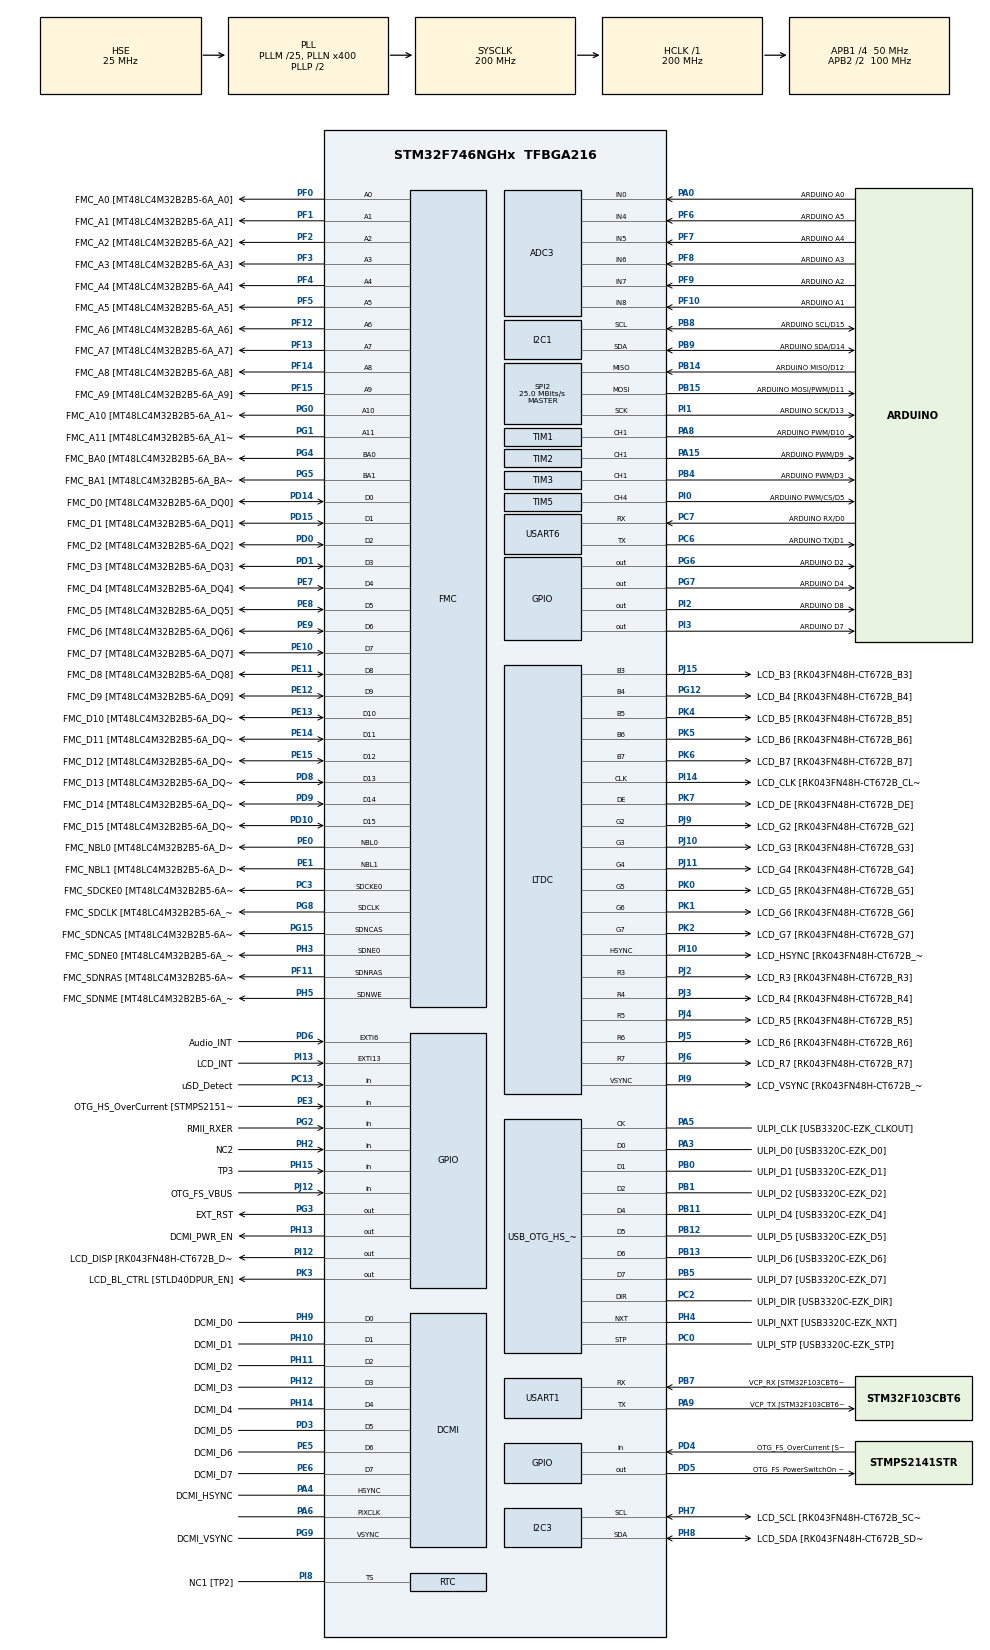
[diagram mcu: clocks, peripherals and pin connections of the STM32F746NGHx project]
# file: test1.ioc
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ADC3.Channel=ADC_CHANNEL_7
ADC3.Channel-0\#ChannelRegularConversion=ADC_CHANNEL_4
ADC3.Channel-IN0=ADC_CHANNEL_0
ADC3.Channel-IN4=ADC_CHANNEL_4
ADC3.Channel-IN5=ADC_CHANNEL_5
ADC3.Channel-IN6=ADC_CHANNEL_6
ADC3.Channel-IN7=ADC_CHANNEL_7
ADC3.Channel-IN8=ADC_CHANNEL_8
CORTEX_M7.CPU_DCache=Enabled
CORTEX_M7.CPU_ICache=Enabled
DCMI.ByteSelectMode=DCMI_BSM_ALTERNATE_2
DCMI.LineSelectMode=DCMI_LSM_ALTERNATE_2
DCMI.VSPolarity=DCMI_VSPOLARITY_HIGH
Dma.DCMI.0.Direction=DMA_PERIPH_TO_MEMORY
Dma.DCMI.0.FIFOMode=DMA_FIFOMODE_ENABLE
Dma.DCMI.0.FIFOThreshold=DMA_FIFO_THRESHOLD_FULL
Dma.DCMI.0.Instance=DMA2_Stream1
Dma.DCMI.0.MemBurst=DMA_MBURST_INC4
Dma.DCMI.0.MemDataAlignment=DMA_MDATAALIGN_WORD
Dma.DCMI.0.MemInc=DMA_MINC_ENABLE
Dma.DCMI.0.Mode=DMA_CIRCULAR
Dma.DCMI.0.PeriphBurst=DMA_PBURST_SINGLE
Dma.DCMI.0.PeriphDataAlignment=DMA_PDATAALIGN_WORD
Dma.DCMI.0.PeriphInc=DMA_PINC_DISABLE
Dma.DCMI.0.Priority=DMA_PRIORITY_HIGH
Dma.Request0=DCMI
FMC.CASLatency1=FMC_SDRAM_CAS_LATENCY_3
FMC.ColumnBitsNumber1=FMC_SDRAM_COLUMN_BITS_NUM_8
FMC.ExitSelfRefreshDelay1=7
FMC.LoadToActiveDelay1=2
FMC.RCDDelay1=2
FMC.RPDelay1=2
FMC.RPDelay2=2
FMC.RowCycleDelay1=7
FMC.RowCycleDelay2=7
FMC.SDClockPeriod1=FMC_SDRAM_CLOCK_PERIOD_2
FMC.SDClockPeriod2=FMC_SDRAM_CLOCK_PERIOD_2
FMC.SelfRefreshTime1=4
FMC.WriteRecoveryTime1=3
I2C1.Timing=0x00C0EAFF
I2C3.Timing=0x00C0EAFF
LTDC.ActiveH=240
LTDC.ActiveW=320
LTDC.HSync=1
LTDC.Layers=0
LTDC.PixelFormat_L0=LTDC_PIXEL_FORMAT_RGB565
LTDC.VSPolarity=LTDC_VSPOLARITY_AH
LTDC.VSync=1
LTDC.WindowX0_L1=0
LTDC.WindowX1_L0=320
LTDC.WindowX1_L1=320
LTDC.WindowY0_L1=0
LTDC.WindowY1_L0=240
LTDC.WindowY1_L1=240
Mcu.Family=STM32F7
Mcu.Name=STM32F746NGHx
Mcu.Package=TFBGA216
NVIC.DCMI_IRQn=true\:0\:0\:false\:false\:true\:true\:true\:true
NVIC.DMA2_Stream1_IRQn=true\:0\:0\:false\:false\:true\:false\:true\:true
NVIC.LTDC_ER_IRQn=true\:0\:0\:false\:false\:true\:true\:true\:true
NVIC.LTDC_IRQn=true\:0\:0\:false\:false\:true\:true\:true\:true
NVIC.PriorityGroup=NVIC_PRIORITYGROUP_4
NVIC.TIM6_DAC_IRQn=true\:15\:0\:false\:false\:true\:false\:true\:true
NVIC.TimeBase=TIM6_DAC_IRQn
NVIC.TimeBaseIP=TIM6
PA0/WKUP.GPIO_Label=ARDUINO A0
PA0/WKUP.GPIO_Mode=GPIO_MODE_ANALOG
PA0/WKUP.GPIO_PuPd=GPIO_NOPULL
PA0/WKUP.Signal=ADCx_IN0
PA1.GPIO_Label=RMII_REF_CLK [LAN8742A-CZ-TR_REFCLK0]
PA1.Signal=ETH_REF_CLK
PA10.GPIO_Label=OTG_FS_ID
PA10.Signal=USB_OTG_FS_ID
PA11.GPIO_Label=OTG_FS_N
PA11.Signal=USB_OTG_FS_DM
PA12.GPIO_Label=OTG_FS_P
PA12.Signal=USB_OTG_FS_DP
PA13.GPIO_Label=SWDIO
PA13.Mode=Serial_Wire
PA13.Signal=SYS_JTMS-SWDIO
PA14.GPIO_Label=SWCLK
PA14.Mode=Serial_Wire
PA14.Signal=SYS_JTCK-SWCLK
PA15.GPIO_Label=ARDUINO PWM/D9
PA15.GPIO_ModeDefaultPP=GPIO_MODE_AF_PP
PA15.GPIO_PuPd=GPIO_NOPULL
PA15.GPIO_Speed=GPIO_SPEED_FREQ_LOW
PA15.Signal=S_TIM2_CH1_ETR
PA2.GPIO_Label=RMII_MDIO [LAN8742A-CZ-TR_MDIO]
PA2.Signal=ETH_MDIO
PA3.GPIO_Label=ULPI_D0 [USB3320C-EZK_D0]
PA3.Mode=Host_HS
PA3.Signal=USB_OTG_HS_ULPI_D0
PA4.GPIO_Label=DCMI_HSYNC
PA4.Mode=Slave_8_bits_External_Synchro
PA4.Signal=DCMI_HSYNC
PA5.GPIO_Label=ULPI_CLK [USB3320C-EZK_CLKOUT]
PA5.Mode=Host_HS
PA5.Signal=USB_OTG_HS_ULPI_CK
PA6.Mode=Slave_8_bits_External_Synchro
PA6.Signal=DCMI_PIXCLK
PA7.GPIO_Label=RMII_CRS_DV [LAN8742A-CZ-TR_CRS_DV]
PA7.Signal=ETH_CRS_DV
PA8.GPIO_Label=ARDUINO PWM/D10
PA8.GPIO_ModeDefaultPP=GPIO_MODE_AF_PP
PA8.GPIO_PuPd=GPIO_NOPULL
PA8.GPIO_Speed=GPIO_SPEED_FREQ_LOW
PA8.Signal=S_TIM1_CH1
PA9.GPIO_Label=VCP_TX [STM32F103CBT6_PA3]
PA9.GPIO_Mode=GPIO_MODE_AF_PP
PA9.GPIO_PuPd=GPIO_NOPULL
PA9.GPIO_Speed=GPIO_SPEED_FREQ_LOW
PA9.Mode=Asynchronous
PA9.Signal=USART1_TX
PB0.GPIO_Label=ULPI_D1 [USB3320C-EZK_D1]
PB0.Mode=Host_HS
PB0.Signal=USB_OTG_HS_ULPI_D1
PB1.GPIO_Label=ULPI_D2 [USB3320C-EZK_D2]
PB1.Mode=Host_HS
PB1.Signal=USB_OTG_HS_ULPI_D2
PB10.GPIO_Label=ULPI_D3 [USB3320C-EZK_D3]
PB10.Signal=USB_OTG_HS_ULPI_D3
PB11.GPIO_Label=ULPI_D4 [USB3320C-EZK_D4]
PB11.Mode=Host_HS
PB11.Signal=USB_OTG_HS_ULPI_D4
PB12.GPIO_Label=ULPI_D5 [USB3320C-EZK_D5]
PB12.Mode=Host_HS
PB12.Signal=USB_OTG_HS_ULPI_D5
PB13.GPIO_Label=ULPI_D6 [USB3320C-EZK_D6]
PB13.Mode=Host_HS
PB13.Signal=USB_OTG_HS_ULPI_D6
PB14.GPIO_Label=ARDUINO MISO/D12
PB14.GPIO_Mode=GPIO_MODE_AF_PP
PB14.GPIO_PuPd=GPIO_NOPULL
PB14.GPIO_Speed=GPIO_SPEED_FREQ_LOW
PB14.Mode=Full_Duplex_Master
PB14.Signal=SPI2_MISO
PB15.GPIO_Label=ARDUINO MOSI/PWM/D11
PB15.GPIO_Mode=GPIO_MODE_AF_PP
PB15.GPIO_PuPd=GPIO_NOPULL
PB15.GPIO_Speed=GPIO_SPEED_FREQ_LOW
PB15.Mode=Full_Duplex_Master
PB15.Signal=SPI2_MOSI
PB2.Signal=QUADSPI_CLK
PB3.GPIO_Label=SWO
PB3.Signal=SYS_JTDO-SWO
PB4.GPIO_Label=ARDUINO PWM/D3
PB4.GPIO_ModeDefaultPP=GPIO_MODE_AF_PP
PB4.GPIO_PuPd=GPIO_NOPULL
PB4.GPIO_Speed=GPIO_SPEED_FREQ_LOW
PB4.Signal=S_TIM3_CH1
PB5.GPIO_Label=ULPI_D7 [USB3320C-EZK_D7]
PB5.Mode=Host_HS
PB5.Signal=USB_OTG_HS_ULPI_D7
PB6.GPIO_Label=QSPI_NCS [N25Q128A13EF840E_S]
PB6.Signal=QUADSPI_BK1_NCS
PB7.GPIO_Label=VCP_RX [STM32F103CBT6_PA2]
PB7.GPIO_Mode=GPIO_MODE_AF_PP
PB7.GPIO_PuPd=GPIO_NOPULL
PB7.GPIO_Speed=GPIO_SPEED_FREQ_LOW
PB7.Mode=Asynchronous
PB7.Signal=USART1_RX
PB8.GPIO_Label=ARDUINO SCL/D15
PB8.GPIO_Mode=GPIO_MODE_AF_OD
PB8.GPIO_Pu=GPIO_PULLUP
PB8.GPIO_PuPd=GPIO_NOPULL
PB8.GPIO_Speed=GPIO_SPEED_FREQ_LOW
PB8.Mode=I2C
PB8.Signal=I2C1_SCL
PB9.GPIO_Label=ARDUINO SDA/D14
PB9.GPIO_Mode=GPIO_MODE_AF_OD
PB9.GPIO_Pu=GPIO_PULLUP
PB9.GPIO_PuPd=GPIO_NOPULL
PB9.GPIO_Speed=GPIO_SPEED_FREQ_LOW
PB9.Mode=I2C
PB9.Signal=I2C1_SDA
PC0.GPIO_Label=ULPI_STP [USB3320C-EZK_STP]
PC0.Mode=Host_HS
PC0.Signal=USB_OTG_HS_ULPI_STP
PC1.GPIO_Label=RMII_MDC [LAN8742A-CZ-TR_MDC]
PC1.Signal=ETH_MDC
PC10.GPIO_Label=SDMMC_D2
PC10.Signal=SDMMC1_D2
PC11.GPIO_Label=SDMMC_D3
PC11.Signal=SDMMC1_D3
PC12.GPIO_Label=SDMMC_CK
PC12.Signal=SDMMC1_CK
PC13.GPIO_Label=uSD_Detect
PC13.Signal=GPIO_Input
PC14/OSC32_IN.GPIO_Label=RCC_OSC32_IN
PC14/OSC32_IN.Mode=LSE-External-Oscillator
PC14/OSC32_IN.Signal=RCC_OSC32_IN
PC15/OSC32_OUT.GPIO_Label=RCC_OSC32_OUT
PC15/OSC32_OUT.Mode=LSE-External-Oscillator
PC15/OSC32_OUT.Signal=RCC_OSC32_OUT
PC2.GPIO_Label=ULPI_DIR [USB3320C-EZK_DIR]
PC2.Mode=Host_HS
PC2.Signal=USB_OTG_HS_ULPI_DIR
PC3.GPIO_Label=FMC_SDCKE0 [MT48LC4M32B2B5-6A_CKE]
PC3.Mode=SdramChipSelect1_1
PC3.Signal=FMC_SDCKE0
PC4.GPIO_Label=RMII_RXD0 [LAN8742A-CZ-TR_RXD0]
PC4.Signal=ETH_RXD0
PC5.GPIO_Label=RMII_RXD1 [LAN8742A-CZ-TR_RXD1]
PC5.Signal=ETH_RXD1
PC6.GPIO_Label=ARDUINO TX/D1
PC6.Mode=Asynchronous
PC6.Signal=USART6_TX
PC7.GPIO_Label=ARDUINO RX/D0
PC7.Mode=Asynchronous
PC7.Signal=USART6_RX
PC8.Signal=SDMMC1_D0
PC9.Signal=SDMMC1_D1
PD0.GPIO_Label=FMC_D2 [MT48LC4M32B2B5-6A_DQ2]
PD0.Signal=FMC_D2_DA2
PD1.GPIO_Label=FMC_D3 [MT48LC4M32B2B5-6A_DQ3]
PD1.Signal=FMC_D3_DA3
PD10.GPIO_Label=FMC_D15 [MT48LC4M32B2B5-6A_DQ15]
PD10.Signal=FMC_D15_DA15
PD11.GPIO_Label=QSPI_D0 [N25Q128A13EF840E_DQ0]
PD11.Signal=QUADSPI_BK1_IO0
PD12.GPIO_Label=QSPI_D1 [N25Q128A13EF840E_DQ1]
PD12.Signal=QUADSPI_BK1_IO1
PD13.GPIO_Label=QSPI_D3 [N25Q128A13EF840E_DQ3]
PD13.Signal=QUADSPI_BK1_IO3
PD14.GPIO_Label=FMC_D0 [MT48LC4M32B2B5-6A_DQ0]
PD14.Signal=FMC_D0_DA0
PD15.GPIO_Label=FMC_D1 [MT48LC4M32B2B5-6A_DQ1]
PD15.Signal=FMC_D1_DA1
PD2.GPIO_Label=SDMMC_CMD
PD2.Signal=SDMMC1_CMD
PD3.GPIO_Label=DCMI_D5
PD3.Mode=Slave_8_bits_External_Synchro
PD3.Signal=DCMI_D5
PD4.GPIO_Label=OTG_FS_OverCurrent [STMPS2141STR_Fault]
PD4.Signal=GPIO_Input
PD5.GPIO_Label=OTG_FS_PowerSwitchOn [STMPS2141STR_EN]
PD5.PinState=GPIO_PIN_SET
PD5.Signal=GPIO_Output
PD6.GPIO_Label=Audio_INT
PD6.GPIO_ModeDefaultEXTI=GPIO_MODE_EVT_RISING
PD6.Signal=GPXTI6
PD7.GPIO_Label=SPDIF_RX0 [74LVC1G04SE_4]
PD7.Signal=SPDIFRX_IN0
PD8.GPIO_Label=FMC_D13 [MT48LC4M32B2B5-6A_DQ13]
PD8.Signal=FMC_D13_DA13
PD9.GPIO_Label=FMC_D14 [MT48LC4M32B2B5-6A_DQ14]
PD9.Signal=FMC_D14_DA14
PE0.GPIO_Label=FMC_NBL0 [MT48LC4M32B2B5-6A_DQM0]
PE0.Signal=FMC_NBL0
PE1.GPIO_Label=FMC_NBL1 [MT48LC4M32B2B5-6A_DQM1]
PE1.Signal=FMC_NBL1
PE10.GPIO_Label=FMC_D7 [MT48LC4M32B2B5-6A_DQ7]
PE10.Signal=FMC_D7_DA7
PE11.GPIO_Label=FMC_D8 [MT48LC4M32B2B5-6A_DQ8]
PE11.Signal=FMC_D8_DA8
PE12.GPIO_Label=FMC_D9 [MT48LC4M32B2B5-6A_DQ9]
PE12.Signal=FMC_D9_DA9
PE13.GPIO_Label=FMC_D10 [MT48LC4M32B2B5-6A_DQ10]
PE13.Signal=FMC_D10_DA10
PE14.GPIO_Label=FMC_D11 [MT48LC4M32B2B5-6A_DQ11]
PE14.Signal=FMC_D11_DA11
PE15.GPIO_Label=FMC_D12 [MT48LC4M32B2B5-6A_DQ12]
PE15.Signal=FMC_D12_DA12
PE2.GPIO_Label=QSPI_D2 [N25Q128A13EF840E_DQ2]
PE2.Signal=QUADSPI_BK1_IO2
PE3.GPIO_Label=OTG_HS_OverCurrent [STMPS2151STR_FAULT]
PE3.Signal=GPIO_Input
PE4.GPIO_Label=LCD_B0 [RK043FN48H-CT672B_B0]
PE4.Signal=LTDC_B0
PE5.GPIO_Label=DCMI_D6
PE5.Mode=Slave_8_bits_External_Synchro
PE5.Signal=DCMI_D6
PE6.GPIO_Label=DCMI_D7
PE6.Mode=Slave_8_bits_External_Synchro
PE6.Signal=DCMI_D7
PE7.GPIO_Label=FMC_D4 [MT48LC4M32B2B5-6A_DQ4]
PE7.Signal=FMC_D4_DA4
PE8.GPIO_Label=FMC_D5 [MT48LC4M32B2B5-6A_DQ5]
PE8.Signal=FMC_D5_DA5
PE9.GPIO_Label=FMC_D6 [MT48LC4M32B2B5-6A_DQ6]
PE9.Signal=FMC_D6_DA6
PF0.GPIO_Label=FMC_A0 [MT48LC4M32B2B5-6A_A0]
PF0.Signal=FMC_A0
PF1.GPIO_Label=FMC_A1 [MT48LC4M32B2B5-6A_A1]
PF1.Signal=FMC_A1
PF10.GPIO_Label=ARDUINO A1
PF10.GPIO_Mode=GPIO_MODE_ANALOG
PF10.GPIO_PuPd=GPIO_NOPULL
PF10.Mode=IN8
PF10.Signal=ADC3_IN8
PF11.GPIO_Label=FMC_SDNRAS [MT48LC4M32B2B5-6A_RAS]
PF11.Signal=FMC_SDNRAS
PF12.GPIO_Label=FMC_A6 [MT48LC4M32B2B5-6A_A6]
PF12.Signal=FMC_A6
PF13.GPIO_Label=FMC_A7 [MT48LC4M32B2B5-6A_A7]
PF13.Signal=FMC_A7
PF14.GPIO_Label=FMC_A8 [MT48LC4M32B2B5-6A_A8]
PF14.Signal=FMC_A8
PF15.GPIO_Label=FMC_A9 [MT48LC4M32B2B5-6A_A9]
PF15.Signal=FMC_A9
PF2.GPIO_Label=FMC_A2 [MT48LC4M32B2B5-6A_A2]
PF2.Signal=FMC_A2
PF3.GPIO_Label=FMC_A3 [MT48LC4M32B2B5-6A_A3]
PF3.Signal=FMC_A3
PF4.GPIO_Label=FMC_A4 [MT48LC4M32B2B5-6A_A4]
PF4.Signal=FMC_A4
PF5.GPIO_Label=FMC_A5 [MT48LC4M32B2B5-6A_A5]
PF5.Signal=FMC_A5
PF6.GPIO_Label=ARDUINO A5
PF6.GPIO_Mode=GPIO_MODE_ANALOG
PF6.GPIO_PuPd=GPIO_NOPULL
PF6.Mode=IN4
PF6.Signal=ADC3_IN4
PF7.GPIO_Label=ARDUINO A4
PF7.GPIO_Mode=GPIO_MODE_ANALOG
PF7.GPIO_PuPd=GPIO_NOPULL
PF7.Mode=IN5
PF7.Signal=ADC3_IN5
PF8.GPIO_Label=ARDUINO A3
PF8.GPIO_Mode=GPIO_MODE_ANALOG
PF8.GPIO_PuPd=GPIO_NOPULL
PF8.Mode=IN6
PF8.Signal=ADC3_IN6
PF9.GPIO_Label=ARDUINO A2
PF9.GPIO_Mode=GPIO_MODE_ANALOG
PF9.GPIO_PuPd=GPIO_NOPULL
PF9.Mode=IN7
PF9.Signal=ADC3_IN7
PG0.GPIO_Label=FMC_A10 [MT48LC4M32B2B5-6A_A10]
PG0.Signal=FMC_A10
PG1.GPIO_Label=FMC_A11 [MT48LC4M32B2B5-6A_A11]
PG1.Signal=FMC_A11
PG10.GPIO_Label=SAI2_SDB [WM8994ECS/R_ADCDAT1]
PG10.Signal=SAI2_SD_B
PG11.GPIO_Label=RMII_TX_EN [LAN8742A-CZ-TR_TXEN]
PG11.Signal=ETH_TX_EN
PG12.GPIO_Label=LCD_B4 [RK043FN48H-CT672B_B4]
PG12.Mode=RGB565
PG12.Signal=LTDC_B4
PG13.GPIO_Label=RMII_TXD0 [LAN8742A-CZ-TR_TXD0]
PG13.Signal=ETH_TXD0
PG14.GPIO_Label=RMII_TXD1 [LAN8742A-CZ-TR_TXD1]
PG14.Signal=ETH_TXD1
PG15.GPIO_Label=FMC_SDNCAS [MT48LC4M32B2B5-6A_CAS]
PG15.Signal=FMC_SDNCAS
PG2.GPIO_Label=RMII_RXER
PG2.Signal=GPIO_Input
PG3.GPIO_Label=EXT_RST
PG3.Signal=GPIO_Output
PG4.GPIO_Label=FMC_BA0 [MT48LC4M32B2B5-6A_BA0]
PG4.Signal=FMC_A14_BA0
PG5.GPIO_Label=FMC_BA1 [MT48LC4M32B2B5-6A_BA1]
PG5.Signal=FMC_A15_BA1
PG6.GPIO_Label=ARDUINO D2
PG6.Signal=GPIO_Output
PG7.GPIO_Label=ARDUINO D4
PG7.Signal=GPIO_Output
PG8.GPIO_Label=FMC_SDCLK [MT48LC4M32B2B5-6A_CLK]
PG8.Signal=FMC_SDCLK
PG9.GPIO_Label=DCMI_VSYNC
PG9.Mode=Slave_8_bits_External_Synchro
PG9.Signal=DCMI_VSYNC
PH0/OSC_IN.GPIO_Label=OSC_25M [NZ2520SB-25.00M_OUT]
PH0/OSC_IN.Mode=HSE-External-Oscillator
PH0/OSC_IN.Signal=RCC_OSC_IN
PH1/OSC_OUT.Mode=HSE-External-Oscillator
PH1/OSC_OUT.Signal=RCC_OSC_OUT
PH10.GPIO_Label=DCMI_D1
PH10.Mode=Slave_8_bits_External_Synchro
PH10.Signal=DCMI_D1
PH11.GPIO_Label=DCMI_D2
PH11.Mode=Slave_8_bits_External_Synchro
PH11.Signal=DCMI_D2
PH12.GPIO_Label=DCMI_D3
PH12.Mode=Slave_8_bits_External_Synchro
PH12.Signal=DCMI_D3
PH13.GPIO_Label=DCMI_PWR_EN
PH13.Signal=GPIO_Output
PH14.GPIO_Label=DCMI_D4
PH14.Mode=Slave_8_bits_External_Synchro
PH14.Signal=DCMI_D4
PH15.GPIO_Label=TP3
PH15.Signal=GPIO_Input
PH2.GPIO_Label=NC2
PH2.Signal=GPIO_Input
PH3.GPIO_Label=FMC_SDNE0 [MT48LC4M32B2B5-6A_CS]
PH3.Mode=SdramChipSelect1_1
PH3.Signal=FMC_SDNE0
PH4.GPIO_Label=ULPI_NXT [USB3320C-EZK_NXT]
PH4.Mode=Host_HS
PH4.Signal=USB_OTG_HS_ULPI_NXT
PH5.GPIO_Label=FMC_SDNME [MT48LC4M32B2B5-6A_WE]
PH5.Signal=FMC_SDNWE
PH6.GPIO_Label=ARDUINO PWM/D6
PH6.Signal=S_TIM12_CH1
PH7.GPIO_Label=LCD_SCL [RK043FN48H-CT672B_SCL]
PH7.GPIO_Pu=GPIO_PULLUP
PH7.Mode=I2C
PH7.Signal=I2C3_SCL
PH8.GPIO_Label=LCD_SDA [RK043FN48H-CT672B_SDA]
PH8.GPIO_Pu=GPIO_PULLUP
PH8.Mode=I2C
PH8.Signal=I2C3_SDA
PH9.GPIO_Label=DCMI_D0
PH9.Mode=Slave_8_bits_External_Synchro
PH9.Signal=DCMI_D0
PI0.GPIO_Label=ARDUINO PWM/CS/D5
PI0.GPIO_ModeDefaultPP=GPIO_MODE_AF_PP
PI0.GPIO_PuPd=GPIO_NOPULL
PI0.GPIO_Speed=GPIO_SPEED_FREQ_LOW
PI0.Signal=S_TIM5_CH4
PI1.GPIO_Label=ARDUINO SCK/D13
PI1.GPIO_Mode=GPIO_MODE_AF_PP
PI1.GPIO_PuPd=GPIO_NOPULL
PI1.GPIO_Speed=GPIO_SPEED_FREQ_LOW
PI1.Mode=Full_Duplex_Master
PI1.Signal=SPI2_SCK
PI10.GPIO_Label=LCD_HSYNC [RK043FN48H-CT672B_HSYNC]
PI10.Mode=RGB565
PI10.Signal=LTDC_HSYNC
PI12.GPIO_Label=LCD_DISP [RK043FN48H-CT672B_DISP] 
PI12.PinState=GPIO_PIN_SET
PI12.Signal=GPIO_Output
PI13.GPIO_Label=LCD_INT
PI13.GPIO_ModeDefaultEXTI=GPIO_MODE_EVT_RISING
PI13.Signal=GPXTI13
PI14.GPIO_Label=LCD_CLK [RK043FN48H-CT672B_CLK]
PI14.Mode=RGB565
PI14.Signal=LTDC_CLK
PI15.GPIO_Label=LCD_R0 [RK043FN48H-CT672B_R0]
PI15.Signal=LTDC_R0
PI2.GPIO_Label=ARDUINO D8
PI2.Signal=GPIO_Output
PI3.GPIO_Label=ARDUINO D7
PI3.Signal=GPIO_Output
PI4.GPIO_Label=SAI2_MCLKA [WM8994ECS/R_MCLK1]
PI4.Signal=SAI2_MCLK_A
PI5.GPIO_Label=SAI2_SCKA [WM8994ECS/R_BCLK1]
PI5.Signal=SAI2_SCK_A
PI6.GPIO_Label=SAI2_SDA [WM8994ECS/R_DACDAT1]
PI6.Signal=SAI2_SD_A
PI7.GPIO_Label=SAI2_FSA [WM8994ECS/R_LRCLK1]
PI7.Signal=SAI2_FS_A
PI8.GPIO_Label=NC1 [TP2]
PI8.Mode=Timestamp enabled - Input Enabled to TS
PI8.Signal=RTC_TS
PI9.GPIO_Label=LCD_VSYNC [RK043FN48H-CT672B_VSYNC]
PI9.Mode=RGB565
PI9.Signal=LTDC_VSYNC
PJ0.GPIO_Label=LCD_R1 [RK043FN48H-CT672B_R1]
PJ0.Signal=LTDC_R1
PJ1.GPIO_Label=LCD_R2 [RK043FN48H-CT672B_R2]
PJ1.Signal=LTDC_R2
PJ10.GPIO_Label=LCD_G3 [RK043FN48H-CT672B_G3]
PJ10.Mode=RGB565
PJ10.Signal=LTDC_G3
PJ11.GPIO_Label=LCD_G4 [RK043FN48H-CT672B_G4]
PJ11.Mode=RGB565
PJ11.Signal=LTDC_G4
PJ12.GPIO_Label=OTG_FS_VBUS
PJ12.Signal=GPIO_Input
PJ13.GPIO_Label=LCD_B1 [RK043FN48H-CT672B_B1]
PJ13.Signal=LTDC_B1
PJ14.GPIO_Label=LCD_B2 [RK043FN48H-CT672B_B2]
PJ14.Signal=LTDC_B2
PJ15.GPIO_Label=LCD_B3 [RK043FN48H-CT672B_B3]
PJ15.Mode=RGB565
PJ15.Signal=LTDC_B3
PJ2.GPIO_Label=LCD_R3 [RK043FN48H-CT672B_R3]
PJ2.Mode=RGB565
PJ2.Signal=LTDC_R3
PJ3.GPIO_Label=LCD_R4 [RK043FN48H-CT672B_R4]
PJ3.Mode=RGB565
PJ3.Signal=LTDC_R4
PJ4.GPIO_Label=LCD_R5 [RK043FN48H-CT672B_R5]
PJ4.Mode=RGB565
PJ4.Signal=LTDC_R5
PJ5.GPIO_Label=LCD_R6 [RK043FN48H-CT672B_R6]
PJ5.Mode=RGB565
PJ5.Signal=LTDC_R6
PJ6.GPIO_Label=LCD_R7 [RK043FN48H-CT672B_R7]
PJ6.Mode=RGB565
PJ6.Signal=LTDC_R7
PJ7.GPIO_Label=LCD_G0 [RK043FN48H-CT672B_G0]
PJ7.Signal=LTDC_G0
PJ8.GPIO_Label=LCD_G1 [RK043FN48H-CT672B_G1]
PJ8.Signal=LTDC_G1
PJ9.GPIO_Label=LCD_G2 [RK043FN48H-CT672B_G2]
PJ9.Mode=RGB565
PJ9.Signal=LTDC_G2
PK0.GPIO_Label=LCD_G5 [RK043FN48H-CT672B_G5]
PK0.Mode=RGB565
PK0.Signal=LTDC_G5
PK1.GPIO_Label=LCD_G6 [RK043FN48H-CT672B_G6]
PK1.Mode=RGB565
PK1.Signal=LTDC_G6
PK2.GPIO_Label=LCD_G7 [RK043FN48H-CT672B_G7]
PK2.Mode=RGB565
PK2.Signal=LTDC_G7
PK3.GPIO_Label=LCD_BL_CTRL [STLD40DPUR_EN]
PK3.GPIO_Speed=GPIO_SPEED_FREQ_LOW
PK3.PinState=GPIO_PIN_SET
PK3.Signal=GPIO_Output
PK4.GPIO_Label=LCD_B5 [RK043FN48H-CT672B_B5]
PK4.Mode=RGB565
PK4.Signal=LTDC_B5
PK5.GPIO_Label=LCD_B6 [RK043FN48H-CT672B_B6]
PK5.Mode=RGB565
PK5.Signal=LTDC_B6
PK6.GPIO_Label=LCD_B7 [RK043FN48H-CT672B_B7]
PK6.Mode=RGB565
PK6.Signal=LTDC_B7
PK7.GPIO_Label=LCD_DE [RK043FN48H-CT672B_DE]
PK7.Mode=RGB565
PK7.Signal=LTDC_DE
ProjectManager.HeapSize=0x2000
ProjectManager.StackSize=0x2000
ProjectManager.TargetToolchain=MDK-ARM V5.32
RCC.AHBFreq_Value=200000000
RCC.APB1CLKDivider=RCC_HCLK_DIV4
RCC.APB1Freq_Value=50000000
RCC.APB1TimFreq_Value=100000000
RCC.APB2CLKDivider=RCC_HCLK_DIV2
RCC.APB2Freq_Value=100000000
RCC.APB2TimFreq_Value=200000000
RCC.CortexFreq_Value=200000000
RCC.HCLKFreq_Value=200000000
RCC.HSE_VALUE=25000000
RCC.HSI_VALUE=16000000
RCC.PLL48CLockSelection=RCC_CLK48SOURCE_PLLSAIP
RCC.PLLI2SN=100
RCC.PLLM=25
RCC.PLLN=400
RCC.PLLQ=9
RCC.PLLSAIN=288
RCC.PLLSAIP=RCC_PLLSAIP_DIV8
RCC.PLLSAIR=4
RCC.PLLSAIRDiv=RCC_PLLSAIDIVR_8
RCC.PLLSourceVirtual=RCC_PLLSOURCE_HSE
RCC.SDMMCClockSelection=RCC_SDMMC1CLKSOURCE_CLK48
RCC.SYSCLKFreq_VALUE=200000000
RCC.SYSCLKSource=RCC_SYSCLKSOURCE_PLLCLK
RCC.USBFreq_Value=36000000
RCC.VCOOutputFreq_Value=400000000
SH.ADCx_IN0.0=ADC3_IN0,IN0
SH.FMC_A0.0=FMC_A0,12b-sda1
SH.FMC_A1.0=FMC_A1,12b-sda1
SH.FMC_A10.0=FMC_A10,12b-sda1
SH.FMC_A11.0=FMC_A11,12b-sda1
SH.FMC_A14_BA0.0=FMC_BA0,FourSdramBanks1
SH.FMC_A15_BA1.0=FMC_BA1,FourSdramBanks1
SH.FMC_A2.0=FMC_A2,12b-sda1
SH.FMC_A3.0=FMC_A3,12b-sda1
SH.FMC_A4.0=FMC_A4,12b-sda1
SH.FMC_A5.0=FMC_A5,12b-sda1
SH.FMC_A6.0=FMC_A6,12b-sda1
SH.FMC_A7.0=FMC_A7,12b-sda1
SH.FMC_A8.0=FMC_A8,12b-sda1
SH.FMC_A9.0=FMC_A9,12b-sda1
SH.FMC_D0_DA0.0=FMC_D0,sd-16b-d1
SH.FMC_D10_DA10.0=FMC_D10,sd-16b-d1
SH.FMC_D11_DA11.0=FMC_D11,sd-16b-d1
SH.FMC_D12_DA12.0=FMC_D12,sd-16b-d1
SH.FMC_D13_DA13.0=FMC_D13,sd-16b-d1
SH.FMC_D14_DA14.0=FMC_D14,sd-16b-d1
SH.FMC_D15_DA15.0=FMC_D15,sd-16b-d1
SH.FMC_D1_DA1.0=FMC_D1,sd-16b-d1
SH.FMC_D2_DA2.0=FMC_D2,sd-16b-d1
SH.FMC_D3_DA3.0=FMC_D3,sd-16b-d1
SH.FMC_D4_DA4.0=FMC_D4,sd-16b-d1
SH.FMC_D5_DA5.0=FMC_D5,sd-16b-d1
SH.FMC_D6_DA6.0=FMC_D6,sd-16b-d1
SH.FMC_D7_DA7.0=FMC_D7,sd-16b-d1
SH.FMC_D8_DA8.0=FMC_D8,sd-16b-d1
SH.FMC_D9_DA9.0=FMC_D9,sd-16b-d1
SH.FMC_NBL0.0=FMC_NBL0,Sd2ByteEnable1
SH.FMC_NBL1.0=FMC_NBL1,Sd2ByteEnable1
SH.FMC_SDCLK.0=FMC_SDCLK,12b-sda1
SH.FMC_SDNCAS.0=FMC_SDNCAS,12b-sda1
SH.FMC_SDNRAS.0=FMC_SDNRAS,12b-sda1
SH.FMC_SDNWE.0=FMC_SDNWE,12b-sda1
SH.S_TIM12_CH1.0=TIM12_CH1
SH.S_TIM1_CH1.0=TIM1_CH1,PWM Generation1 CH1
SH.S_TIM2_CH1_ETR.0=TIM2_CH1,PWM Generation1 CH1
SH.S_TIM3_CH1.0=TIM3_CH1,PWM Generation1 CH1
SH.S_TIM5_CH4.0=TIM5_CH4,PWM Generation4 CH4
SPI2.BaudRatePrescaler=SPI_BAUDRATEPRESCALER_2
SPI2.CalculateBaudRate=25.0 MBits/s
SPI2.Direction=SPI_DIRECTION_2LINES
SPI2.Mode=SPI_MODE_MASTER
SPI2.VirtualType=VM_MASTER
STMicroelectronics.X-CUBE-AI.8.0.1.ActivationBufferSizeList=46112,120208
STMicroelectronics.X-CUBE-AI.8.0.1.ActivationBuffers=pool0;pool0
STMicroelectronics.X-CUBE-AI.8.0.1.ActivationNames=pool0
STMicroelectronics.X-CUBE-AI.8.0.1.ActivationSizes=AI_NETWORK_1_DATA_ACTIVATION_1_SIZE
STMicroelectronics.X-CUBE-AI.8.0.1.HeapSize=0x2000
STMicroelectronics.X-CUBE-AI.8.0.1.InternalRamActivationBufferMaxSize=AI_NETWORK_1_DATA_ACTIVATIONS_SIZE
STMicroelectronics.X-CUBE-AI.8.0.1.LatestDirectoryUsed-85fdcf0217d4680b0ca563112c731b353d7d683e6cb36050074070efd486d68f=E\:\\FaceProjects\\Facemodel2
STMicroelectronics.X-CUBE-AI.8.0.1.LatestDirectoryUsed-f0d4407576579c9e54b741f97cf1a07df4638932aca9199125f75c0dc9ac62df=E\:\\FaceProjects\\yoloface-50k-main\\tflite
STMicroelectronics.X-CUBE-AI.8.0.1.MaximumNumberOfInputLayer=1
STMicroelectronics.X-CUBE-AI.8.0.1.MaximumNumberOfOutputLayer=1
STMicroelectronics.X-CUBE-AI.8.0.1.MaximumSizeOfInputLayer=1
STMicroelectronics.X-CUBE-AI.8.0.1.MaximumSizeOfOutputLayer=1
STMicroelectronics.X-CUBE-AI.8.0.1.ModelActualCompression-85fdcf0217d4680b0ca563112c731b353d7d683e6cb36050074070efd486d68f=0.0
STMicroelectronics.X-CUBE-AI.8.0.1.ModelActualCompression-f0d4407576579c9e54b741f97cf1a07df4638932aca9199125f75c0dc9ac62df=0.0
STMicroelectronics.X-CUBE-AI.8.0.1.ModelCompression-85fdcf0217d4680b0ca563112c731b353d7d683e6cb36050074070efd486d68f=None
STMicroelectronics.X-CUBE-AI.8.0.1.ModelCompression-f0d4407576579c9e54b741f97cf1a07df4638932aca9199125f75c0dc9ac62df=None
STMicroelectronics.X-CUBE-AI.8.0.1.ModelFlashOccupation-85fdcf0217d4680b0ca563112c731b353d7d683e6cb36050074070efd486d68f=127470
STMicroelectronics.X-CUBE-AI.8.0.1.ModelFlashOccupation-f0d4407576579c9e54b741f97cf1a07df4638932aca9199125f75c0dc9ac62df=70414
STMicroelectronics.X-CUBE-AI.8.0.1.ModelHashList=f0d4407576579c9e54b741f97cf1a07df4638932aca9199125f75c0dc9ac62df;85fdcf0217d4680b0ca563112c731b353d7d683e6cb36050074070efd486d68f
STMicroelectronics.X-CUBE-AI.8.0.1.ModelKind-85fdcf0217d4680b0ca563112c731b353d7d683e6cb36050074070efd486d68f=TFLITE
STMicroelectronics.X-CUBE-AI.8.0.1.ModelKind-f0d4407576579c9e54b741f97cf1a07df4638932aca9199125f75c0dc9ac62df=TFLITE
STMicroelectronics.X-CUBE-AI.8.0.1.ModelMacc-85fdcf0217d4680b0ca563112c731b353d7d683e6cb36050074070efd486d68f=10450358
STMicroelectronics.X-CUBE-AI.8.0.1.ModelMacc-f0d4407576579c9e54b741f97cf1a07df4638932aca9199125f75c0dc9ac62df=1381952
STMicroelectronics.X-CUBE-AI.8.0.1.ModelName-85fdcf0217d4680b0ca563112c731b353d7d683e6cb36050074070efd486d68f=network_1
STMicroelectronics.X-CUBE-AI.8.0.1.ModelName-f0d4407576579c9e54b741f97cf1a07df4638932aca9199125f75c0dc9ac62df=network
STMicroelectronics.X-CUBE-AI.8.0.1.ModelNameList=network,network_1
STMicroelectronics.X-CUBE-AI.8.0.1.ModelRamOccupation-85fdcf0217d4680b0ca563112c731b353d7d683e6cb36050074070efd486d68f=120208
STMicroelectronics.X-CUBE-AI.8.0.1.ModelRamOccupation-f0d4407576579c9e54b741f97cf1a07df4638932aca9199125f75c0dc9ac62df=46112
STMicroelectronics.X-CUBE-AI.8.0.1.ModelStructureFile-85fdcf0217d4680b0ca563112c731b353d7d683e6cb36050074070efd486d68f=E\:\\FaceProjects\\Facemodel2\\miniXCEPTION102.tflite
STMicroelectronics.X-CUBE-AI.8.0.1.ModelStructureFile-f0d4407576579c9e54b741f97cf1a07df4638932aca9199125f75c0dc9ac62df=E\:\\FaceProjects\\yoloface-50k-main\\tflite\\yoloface_int8.tflite
STMicroelectronics.X-CUBE-AI.8.0.1.ModelType-85fdcf0217d4680b0ca563112c731b353d7d683e6cb36050074070efd486d68f=STM32Cube.AI runtime
STMicroelectronics.X-CUBE-AI.8.0.1.ModelType-f0d4407576579c9e54b741f97cf1a07df4638932aca9199125f75c0dc9ac62df=STM32Cube.AI runtime
STMicroelectronics.X-CUBE-AI.8.0.1.ReadyForCodeGeneration=true
STMicroelectronics.X-CUBE-AI.8.0.1.StackSize=0x2000
STMicroelectronics.X-CUBE-AI.8.0.1.WorkingBufferStartAddrList=0xFFFFFFFF,0xFFFFFFFF
STMicroelectronics.X-CUBE-AI.8.0.1.XAaCUBEAaAICcArtificialOoIntelligenceJjCore=true
STMicroelectronics.X-CUBE-AI.8.0.1.copyWeightToRam=false
STMicroelectronics.X-CUBE-AI.8.0.1.copyWeightToRam-85fdcf0217d4680b0ca563112c731b353d7d683e6cb36050074070efd486d68f=false
STMicroelectronics.X-CUBE-AI.8.0.1.copyWeightToRam-f0d4407576579c9e54b741f97cf1a07df4638932aca9199125f75c0dc9ac62df=false
STMicroelectronics.X-CUBE-AI.8.0.1.customLayerConfigEnabled=false
STMicroelectronics.X-CUBE-AI.8.0.1.customLayerConfigEnabled-85fdcf0217d4680b0ca563112c731b353d7d683e6cb36050074070efd486d68f=false
STMicroelectronics.X-CUBE-AI.8.0.1.customLayerConfigEnabled-f0d4407576579c9e54b741f97cf1a07df4638932aca9199125f75c0dc9ac62df=false
STMicroelectronics.X-CUBE-AI.8.0.1.useInputAllocation=true
STMicroelectronics.X-CUBE-AI.8.0.1.useInputAllocation-85fdcf0217d4680b0ca563112c731b353d7d683e6cb36050074070efd486d68f=true
STMicroelectronics.X-CUBE-AI.8.0.1.useInputAllocation-f0d4407576579c9e54b741f97cf1a07df4638932aca9199125f75c0dc9ac62df=true
STMicroelectronics.X-CUBE-AI.8.0.1.useOutputAllocation=true
STMicroelectronics.X-CUBE-AI.8.0.1.useOutputAllocation-85fdcf0217d4680b0ca563112c731b353d7d683e6cb36050074070efd486d68f=true
STMicroelectronics.X-CUBE-AI.8.0.1.useOutputAllocation-f0d4407576579c9e54b741f97cf1a07df4638932aca9199125f75c0dc9ac62df=true
STMicroelectronics.X-CUBE-TOUCHGFX.4.22.0.tgfx_custom_height=56
STMicroelectronics.X-CUBE-TOUCHGFX.4.22.0.tgfx_custom_width=56
STMicroelectronics.X-CUBE-TOUCHGFX.4.22.0_IsPackSelfContextualization=true
TIM1.Channel-PWM\ Generation1\ CH1=TIM_CHANNEL_1
TIM2.Channel-PWM\ Generation1\ CH1=TIM_CHANNEL_1
TIM3.Channel-PWM\ Generation1\ CH1=TIM_CHANNEL_1
TIM5.Channel-PWM\ Generation4\ CH4=TIM_CHANNEL_4
USART1.VirtualMode-Asynchronous=VM_ASYNC
USART6.VirtualMode-Asynchronous=VM_ASYNC
VP_CRC_VS_CRC.Mode=CRC_Activate
VP_DMA2D_VS_DMA2D.Mode=DMA2D_Activate
VP_RTC_VS_RTC_Activate.Mode=RTC_Enabled
VP_RTC_VS_RTC_Calendar.Mode=RTC_Calendar
VP_STMicroelectronics.X-CUBE-AI_VS_ArtificialOoIntelligenceJjXAaCUBEAaAI_8.0.1.Mode=ArtificialOoIntelligenceJjXAaCUBEAaAI
VP_SYS_VS_tim6.Mode=TIM6
VP_TIM1_VS_ClockSourceINT.Mode=Internal
VP_TIM2_VS_ClockSourceINT.Mode=Internal
VP_TIM3_VS_ClockSourceINT.Mode=Internal
VP_TIM5_VS_ClockSourceINT.Mode=Internal
board=STM32F746G-DISCO

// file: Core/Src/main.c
/* USER CODE BEGIN Header */
/**
  ******************************************************************************
  * @file           : main.c
  * @brief          : Main program body
  ******************************************************************************
  * @attention
  *
  * Copyright (c) 2023 STMicroelectronics.
  * All rights reserved.
  *
  * This software is licensed under terms that can be found in the LICENSE file
  * in the root directory of this software component.
  * If no LICENSE file comes with this software, it is provided AS-IS.
  *
  ******************************************************************************
  */
/* USER CODE END Header */
#include "main.h"
#include "adc.h"
#include "crc.h"
#include "dcmi.h"
#include "dma.h"
#include "dma2d.h"
#include "i2c.h"
#include "ltdc.h"
#include "rtc.h"
#include "spi.h"
#include "tim.h"
#include "usart.h"
#include "gpio.h"
#include "fmc.h"

/* USER CODE BEGIN Includes */
#include "string.h"
#include "stdio.h"
#include <math.h>
#include "stm32746g_discovery_lcd.h"
#include "stm32746g_discovery_sdram.h"
#include "stm32746g_discovery_camera.h"

#include "ai_platform.h"
#include "network.h"
#include "network_data.h"
#include "network_1.h"
#include "network_1_data.h"

/* USER CODE END Includes */

/* USER CODE BEGIN PTD */
static void AI_Init(void);
static void AI_Run(int *pIn, int *pOut);
static void AI_Init_1(void);
static void AI_Run_1(float *pIn, float *pOut);

static void prepare_yolo_data(uint16_t* image_data);
static void post_process_my(void);

static uint32_t argmax(const float *values, uint32_t len);

/* USER CODE END PTD */

/* USER CODE BEGIN PV */
#define FRAME_BUFFER  0xC0000000
#define SCALE_IMAGE  0xC0200000

/* USER CODE END PV */

void SystemClock_Config(void);
/* USER CODE BEGIN PFP */
uint32_t Im_size = 0;
uint32_t Im_size2 = 0;

ai_handle network;
ai_handle network_1;

int in_data[AI_NETWORK_IN_1_SIZE];
int out_data[AI_NETWORK_OUT_1_SIZE];

float in_data_1[AI_NETWORK_1_IN_1_SIZE];
float out_data_1[AI_NETWORK_1_OUT_1_SIZE];

ai_u8 activations[AI_NETWORK_DATA_ACTIVATIONS_SIZE];
ai_u8 activations_1[AI_NETWORK_1_DATA_ACTIVATIONS_SIZE];

ai_buffer * ai_input;
ai_buffer * ai_output;

ai_buffer * ai_input_1;
ai_buffer * ai_output_1;

//uint16_t temp_data[3136] ;
int x1, y1, x2, y2;                                                  // 人脸方框的左上右下像素坐标
uint8_t anchors[3][2] = {{9, 14}, {12, 17}, {22, 21}};               // yoloface的anchor尺寸
static uint16_t*image_data = (uint16_t*)0xC0200000;

const char *activities[AI_NETWORK_1_OUT_1_SIZE] =
{
    "anger", "disgust", "fear", "happy", "sad", "surprised", "normal"
};
// '0'anger'#生气 , '1':'disgust'#厌恶 , '2':'fear'#恐惧 , '3':'happy'#开心 , '4':'sad'#伤心 , '5':'surprised'#惊讶 , '6':'normal#正常

/* USER CODE END PFP */

int main(void)
{

  /* Enable I-Cache---------------------------------------------------------*/
  SCB_EnableICache();

  /* Enable D-Cache---------------------------------------------------------*/
  SCB_EnableDCache();

  /* MCU Configuration--------------------------------------------------------*/

  /* Reset of all peripherals, Initializes the Flash interface and the Systick. */
  HAL_Init();

  /* Configure the system clock */
  SystemClock_Config();

  /* Initialize all configured peripherals */
  MX_GPIO_Init();
  MX_DMA_Init();
  MX_ADC3_Init();
  MX_CRC_Init();
  MX_DCMI_Init();
  MX_FMC_Init();
  MX_I2C1_Init();
  MX_I2C3_Init();
  MX_RTC_Init();
  MX_SPI2_Init();
  MX_TIM1_Init();
  MX_TIM2_Init();
  MX_TIM3_Init();
  MX_TIM5_Init();
  MX_USART1_UART_Init();
  MX_USART6_UART_Init();
  MX_DMA2D_Init();
  MX_LTDC_Init();
  /* USER CODE BEGIN 2 */
	BSP_LCD_Init();
//	BSP_LCD_SelectLayer(0);
//  BSP_LCD_DisplayStringAt(50, 0, (uint8_t *)"raw picture", CENTER_MODE);
//	HAL_Delay(1000);
//	HAL_Delay(1000);
//  BSP_LCD_Clear(LCD_COLOR_WHITE);

	BSP_LCD_LayerRgb565Init(0, FRAME_BUFFER);                                                            //layer of camera        layer0
	BSP_LCD_LayerRgb565Init(1, FRAME_BUFFER + (BSP_LCD_GetXSize()*BSP_LCD_GetYSize()*4));                //layer of other info
	BSP_CAMERA_Init(CAMERA_R320x240);
	HAL_Delay(100);
  Im_size = 0x9600; //size=320x240*2/4
	HAL_DCMI_Start_DMA(&hdcmi, DCMI_MODE_CONTINUOUS , (uint32_t)FRAME_BUFFER, Im_size);

	BSP_LCD_SelectLayer(LTDC_ACTIVE_LAYER);                                                              //Initialization Interface
	BSP_LCD_SetTransparency(1, 255);
	BSP_LCD_Clear(LCD_COLOR_WHITE);
	BSP_LCD_SetTextColor(LCD_COLOR_RED);
	BSP_LCD_DisplayStringAt(0, 50, (uint8_t *)"TinyML", CENTER_MODE);
	BSP_LCD_DisplayStringAt(0, 120, (uint8_t *)"214 Dont't Emo", CENTER_MODE);
	HAL_Delay(1000);
	HAL_Delay(1000);
	HAL_Delay(1000);
	HAL_Delay(1000);
	BSP_LCD_SetTransparency(1, 100);
	BSP_LCD_Clear(LCD_COLOR_WHITE);

	BSP_LCD_SelectLayer(0);                                                                              //Camera Capture Video
	//BSP_LCD_Clear(LCD_COLOR_TRANSPARENT);
	BSP_LCD_SetTextColor(LCD_COLOR_RED);
	BSP_LCD_DisplayStringAt(5, 245, (uint8_t *)"raw video", CENTER_MODE);
	HAL_Delay(1000);
	HAL_Delay(1000);
	HAL_Delay(1000);
	HAL_Delay(1000);
	BSP_LCD_Clear(LCD_COLOR_WHITE);

//  BSP_CAMERA_Init(CAMERA_R480x272);
//	HAL_Delay(100);
//  Im_size = 0x25800; //size=480*240*2/4
//	HAL_DCMI_Start_DMA(&hdcmi, DCMI_MODE_CONTINUOUS , (uint32_t)LCD_FRAME_BUFFER, Im_size);

//  HAL_Delay(1000);
//	BSP_LCD_Init();
//	TEST_LCD_LayerRgb565Init(LTDC_ACTIVE_LAYER, SCALE_IMAGE);

  /* USER CODE END 2 */

  /* Infinite loop */
  while (1)
  {
		prepare_yolo_data(image_data);
		AI_Init();
    //printf("AI_Run begin :%d\r\n",TIM2->CNT);
		AI_Run(in_data, out_data);
		//printf("AI_Run end :%d\r\n",TIM2->CNT);
		post_process_my();
		//printf("post process end :%d\r\n",TIM2->CNT);
		AI_Init_1();
		AI_Run_1(in_data_1,out_data_1);
		printf("AI_Run end :%d\r\n",TIM2->CNT);

		printf("AI_Run_1 out_data_1 : %f, %f, %f, %f, %f, %f, %f\r\n", out_data_1[0], out_data_1[1], out_data_1[2], out_data_1[3], out_data_1[4], out_data_1[5], out_data_1[6] );

		uint32_t class = argmax(out_data_1, AI_NETWORK_1_OUT_1_SIZE);
		printf(": %d - %s\r\n", (int) class, activities[class]);
		printf("run over\r\n");

		BSP_LCD_DisplayStringAt(5, 245, (uint8_t *)"emotion:", LEFT_MODE);
		BSP_LCD_DisplayStringAt(5, 245, (uint8_t *)(activities[class]), RIGHT_MODE);
		HAL_Delay(1000);
		HAL_Delay(1000);
		HAL_Delay(1000);
		BSP_LCD_Clear(LCD_COLOR_WHITE);

  }
}

void SystemClock_Config(void)
{
  RCC_OscInitTypeDef RCC_OscInitStruct = {0};
  RCC_ClkInitTypeDef RCC_ClkInitStruct = {0};

  /** Configure LSE Drive Capability
  */
  HAL_PWR_EnableBkUpAccess();

  /** Configure the main internal regulator output voltage
  */
  __HAL_RCC_PWR_CLK_ENABLE();
  __HAL_PWR_VOLTAGESCALING_CONFIG(PWR_REGULATOR_VOLTAGE_SCALE1);

  /** Initializes the RCC Oscillators according to the specified parameters
  * in the RCC_OscInitTypeDef structure.
  */
  RCC_OscInitStruct.OscillatorType = RCC_OSCILLATORTYPE_LSI|RCC_OSCILLATORTYPE_HSE;
  RCC_OscInitStruct.HSEState = RCC_HSE_ON;
  RCC_OscInitStruct.LSIState = RCC_LSI_ON;
  RCC_OscInitStruct.PLL.PLLState = RCC_PLL_ON;
  RCC_OscInitStruct.PLL.PLLSource = RCC_PLLSOURCE_HSE;
  RCC_OscInitStruct.PLL.PLLM = 25;
  RCC_OscInitStruct.PLL.PLLN = 400;
  RCC_OscInitStruct.PLL.PLLP = RCC_PLLP_DIV2;
  RCC_OscInitStruct.PLL.PLLQ = 9;
  if (HAL_RCC_OscConfig(&RCC_OscInitStruct) != HAL_OK)
  {
    Error_Handler();
  }

  /** Activate the Over-Drive mode
  */
  if (HAL_PWREx_EnableOverDrive() != HAL_OK)
  {
    Error_Handler();
  }

  /** Initializes the CPU, AHB and APB buses clocks
  */
  RCC_ClkInitStruct.ClockType = RCC_CLOCKTYPE_HCLK|RCC_CLOCKTYPE_SYSCLK
                              |RCC_CLOCKTYPE_PCLK1|RCC_CLOCKTYPE_PCLK2;
  RCC_ClkInitStruct.SYSCLKSource = RCC_SYSCLKSOURCE_PLLCLK;
  RCC_ClkInitStruct.AHBCLKDivider = RCC_SYSCLK_DIV1;
  RCC_ClkInitStruct.APB1CLKDivider = RCC_HCLK_DIV4;
  RCC_ClkInitStruct.APB2CLKDivider = RCC_HCLK_DIV2;

  if (HAL_RCC_ClockConfig(&RCC_ClkInitStruct, FLASH_LATENCY_6) != HAL_OK)
  {
    Error_Handler();
  }
}

/* USER CODE BEGIN 4 */
//========================================================================================WSJ
int fputc(int ch,FILE *f)
{
	HAL_UART_Transmit(&huart1,(uint8_t *)&ch,1,0xFFFF);
	return ch;
}

static void AI_Init(void)
{
  ai_error err;

  /* Create a local array with the addresses of the activations buffers */
  const ai_handle act_addr[] = { activations };
  /* Create an instance of the model */
  err = ai_network_create_and_init(&network, act_addr, NULL);
  if (err.type != AI_ERROR_NONE) {
    printf("ai_network_create error - type=%d code=%d\r\n", err.type, err.code);
    Error_Handler();
  }
  ai_input = ai_network_inputs_get(network, NULL);
  ai_output = ai_network_outputs_get(network, NULL);
}

static void AI_Run(int *pIn, int *pOut)
{
  ai_i32 batch;
  ai_error err;

  /* Update IO handlers with the data payload */
  ai_input[0].data = AI_HANDLE_PTR(pIn);
  ai_output[0].data = AI_HANDLE_PTR(pOut);

  batch = ai_network_run(network, ai_input, ai_output);
  if (batch != 1) {
    err = ai_network_get_error(network);
    printf("AI ai_network_run error - type=%d code=%d\r\n", err.type, err.code);
    Error_Handler();
  }
}

static void AI_Init_1(void)
{
  ai_error err;

  /* Create a local array with the addresses of the activations buffers */
  const ai_handle act_addr[] = { activations_1 };
  /* Create an instance of the model */
  err = ai_network_1_create_and_init(&network_1, act_addr, NULL);
  if (err.type != AI_ERROR_NONE) {
    printf("ai_network_1_create error - type=%d code=%d\r\n", err.type, err.code);
    Error_Handler();
  }
  ai_input_1 = ai_network_1_inputs_get(network_1, NULL);
  ai_output_1 = ai_network_1_outputs_get(network_1, NULL);
}

static void AI_Run_1(float *pIn, float *pOut)
{
  ai_i32 batch;
  ai_error err;

  /* Update IO handlers with the data payload */
  ai_input_1[0].data = AI_HANDLE_PTR(pIn);
  ai_output_1[0].data = AI_HANDLE_PTR(pOut);

  batch = ai_network_1_run(network_1, ai_input_1, ai_output_1);
  if (batch != 1) {
    err = ai_network_1_get_error(network_1);
    printf("AI ai_network_1_run error - type=%d code=%d\r\n", err.type, err.code);
    Error_Handler();
  }
}

void prepare_yolo_data(uint16_t* image_data)
{
	for(int i = 0; i < 3136; i++)
	{
		uint16_t color = image_data[i];
		// 这里要注意，网络的输入张量维度是BHWC，对应1*56*56*3，通道顺序是RGB
					// 所以输入数组的存储顺序应该是先行后列，颜色是R G B
		in_data[i*3] = (uint8_t)((color&0xF800)>>8) - 128;
		in_data[i*3+1] = (uint8_t)((color&0x07E0)>>3) - 128;
		in_data[i*3+2] = (uint8_t)((color&0x001F)<<3) - 128;
	}
}

// 定义sigmoid函数
float sigmoid(float x)
{
	float y = 1/(1+expf(-x));
	return y;
}

#define DEST_WIDTH 64
#define DEST_HEIGHT 64
void resizeFace(int8_t* src, float* dst, int SRC_WIDTH, int SRC_HEIGHT)  //后面的两个参数是上一步裁剪后不确定的长宽，这里是自适应的插值变为64 x 64
	{
    // 计算行和列的缩放比例
    float rowScale = (float)SRC_HEIGHT / DEST_HEIGHT;
    float colScale = (float)SRC_WIDTH / DEST_WIDTH;

    // 遍历目标图像的每一行和每一列
    for (int i = 0; i < DEST_HEIGHT; i++) {
        for (int j = 0; j < DEST_WIDTH; j++) {
            // 计算在原图像中的行和列位置
            float srcRow = i * rowScale;
            float srcCol = j * colScale;

            // 计算左上角像素位置
            int srcRowFloor = (int)floor(srcRow);
            int srcColFloor = (int)floor(srcCol);

            // 计算行和列的偏移量
            float dy = srcRow - srcRowFloor;
            float dx = srcCol - srcColFloor;

            // 计算四个相邻像素在原图像中的线性索引
            int srcIdxTL = srcRowFloor * SRC_WIDTH + srcColFloor;
            int srcIdxTR = srcRowFloor * SRC_WIDTH + (srcColFloor + 1);
            int srcIdxBL = (srcRowFloor + 1) * SRC_WIDTH + srcColFloor;
            int srcIdxBR = (srcRowFloor + 1) * SRC_WIDTH + (srcColFloor + 1);

            // 根据四个相邻像素的插值进行插值计算
            float pixelTL = src[srcIdxTL];
            float pixelTR = src[srcIdxTR];
            float pixelBL = src[srcIdxBL];
            float pixelBR = src[srcIdxBR];

            float interpolatedPixel = (1 - dx) * (1 - dy) * pixelTL +
                                      dx * (1 - dy) * pixelTR +
                                      (1 - dx) * dy * pixelBL +
                                      dx * dy * pixelBR;

            // 在目标图像中的线性索引
            int dstIdx = i * DEST_WIDTH + j;

            // 复制插值后的像素值到目标图像
            dst[dstIdx] = interpolatedPixel;
						dst[dstIdx] = dst[dstIdx] +128;

        }
    }

}

// 网络后处理函数
// 注意，正常的YOLO后处理都应该包含非极大值抑制NMS操作，但因为我比较懒所以没有加，这里只是根据置信度做了初步提取
void post_process_my()
{
	int grid_x, grid_y;
	float x=0, y=0, w=0 ,h=0;
	bool found = false;
	for(int i = 0; i < 49; i++)
	{
		for(int j = 0; j < 3; j++)
		{
            // 网络输出维度是1*7*7*18
            // 其中18维度包含了每个像素预测的三个锚框，每个锚框对应6个维度，依次为x y w h conf class
            // 当然因为这个网络是单类检测，所以class这一维度没有用
			int8_t conf = out_data[i*18+j*6+4];
			printf("conf is %d\r\n", conf);
            // 这里的-9是根据网络量化的缩放偏移量计算的，对应的是70%的置信度
            // sigmoid((conf+15)*0.14218327403068542) < 0.7 ==> conf > -9
			if(conf > -9)
			{
				grid_x = i % 7;
				grid_y = (i - grid_x)/7;
				// 这里的15和0.14218327403068542就是网络量化后给出的缩放偏移量
				x = ((float)out_data[i*18+j*6]+15)*0.14218327403068542f;
				y = ((float)out_data[i*18+j*6+1]+15)*0.14218327403068542f;
				w = ((float)out_data[i*18+j*6+2]+15)*0.14218327403068542f;
				h = ((float)out_data[i*18+j*6+3]+15)*0.14218327403068542f;
                // 网络下采样三次，缩小了8倍，这里给还原回56*56的尺度

				x = (sigmoid(x)+grid_x) * 8;
				y = (sigmoid(y)+grid_y) * 8;
				w = expf(w) * anchors[j][0];
				h = expf(h) * anchors[j][1];
				w=w/3; h=h/3;
				y2 = (x - w/2);
				y2 = 56-y2;
				y1 = (x + w/2);
				y1 = 56-y1;
				x1 = (y - h/2);
				x2 = (y + h/2);
				if(x1 < 0) x1 = 0;
				if(y1 < 0) y1 = 0;
				if(x2 > 55) x2 = 55;
				if(y2 > 55) y2 = 55;

				printf("x1:%d, x2:%d, y1:%d ,y2:%d ,w:%f ,h:%f ,x:%f ,y:%f \r\n", x1, x2, y1, y2, w, h, x, y);
         // 绘制方框，左上角坐标为(x1, y1)，右下角坐标为(x2, y2)
         // 注意，如果输入图像是缩放到56*56再输入网络的话，这里的坐标还要乘以图像的缩放系数

				// 创建一个新的数组用于存储裁剪后的像素
				int8_t cropped_data[(y2-y1+1) * (x2-x1+1)];

				for(int i = y1; i <= y2; i++)
				{
						for(int j = x1; j <= x2; j++)
						{
								// 将RGB三通道转换为单通道
								cropped_data[(i-y1)*(x2-x1+1) + (j-x1)] = in_data[((i-1)*56+(j-1))*3] * 0.299 + in_data[((i-1)*56+(j-1))*3+1] * 0.587 + in_data[((i-1)*56+(j-1))*3+2] * 0.144;
						}
				}

//				  for(int i=0; i < ((y2-y1+1) * (x2-x1+1)); i++)
//					{
//						printf(" %d,", cropped_data[i]+128);
//					}

				// 使用插值算法进行缩放
				printf("cropped img size is %d  X %d\r\n",y2-y1+1,x2-x1+1);
				resizeFace(cropped_data, in_data_1, x2-x1+1, y2-y1+1);

				BSP_LCD_SelectLayer(LTDC_ACTIVE_LAYER);                                                              //Show inference results
				BSP_LCD_Clear(LCD_COLOR_WHITE);
				BSP_LCD_DrawRect(x1*5.7143, y1*4.286, (x2-x1)*5.7143, (y2-y1)*4.286);                                            //画框，此处需要乘56*56到320*240的偏移量

        found = true;
				break;
			}

		}
				if(found)  // 如果找到符合条件的锚框，则跳出外层循环
				{
				break;
				}
	}
}

static uint32_t argmax(const float *values, uint32_t len)
{
    float max_value = values[0];
    uint32_t max_index = 0;
    for (uint32_t i = 1; i < len; i++)
    {
        if (values[i] > max_value)
        {
            max_value = values[i];
            max_index = i;
        }
    }
    return max_index;
}

/* USER CODE END 4 */

void HAL_TIM_PeriodElapsedCallback(TIM_HandleTypeDef *htim)
{
  if (htim->Instance == TIM6) {
    HAL_IncTick();
  }
}

void Error_Handler(void)
{
  __disable_irq();
  while (1)
  {
  }
}
